# R7FA2L1AB register map
Vendor: Renesas Electronics Corporation; Series: RA2L1; File version: 1.30.00
CPU: CM23 r1p0, little endian, MPU, no FPU, VTOR, 2 interrupt priority bits, 32 interrupts
Registers are 8-bit, read-write, reset 0x0 unless marked. A register's access mark holds for its fields unless they carry their own. Offsets are from the block's base; [hi:lo] are bit positions; {n}, {i} and the like mark numbered series.

## ICU — ICU for CPU
Base 0x40006000
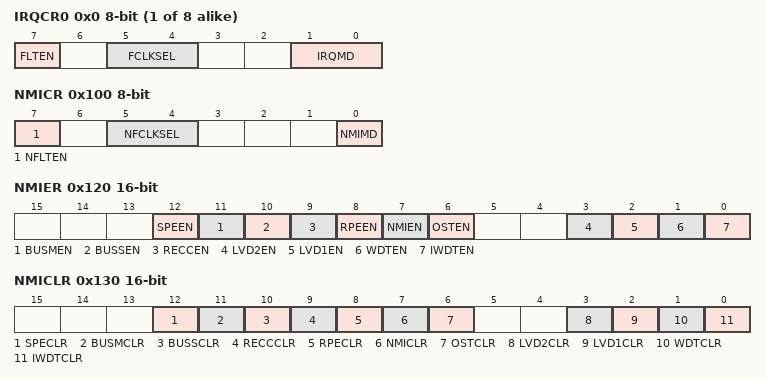
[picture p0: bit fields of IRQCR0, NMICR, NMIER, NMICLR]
{0x0+i} IRQCR{i} (i=0..7) — IRQ Control Register {i}
  [7] FLTEN — IRQi Digital Filter Enable
    0=Digital filter is disabled; 1=Digital filter is enabled
  [5:4] FCLKSEL — IRQi Digital Filter Sampling Clock Select
    0=PCLKB; 1=PCLKB/8; 2=PCLKB/32; 3=PCLKB/64
  [1:0] IRQMD — IRQi Detection Sense Select
    0=Falling edge; 1=Rising edge; 2=Rising and falling edges; 3=Low level
0x100 NMICR — NMI Pin Interrupt Control Register
  [7] NFLTEN — NMI Digital Filter Enable
    0=Disabled; 1=Enabled
  [5:4] NFCLKSEL — NMI Digital Filter Sampling Clock Select
    0=PCLKB; 1=PCLKB/8; 2=PCLKB/32; 3=PCLKB/64
  [0] NMIMD — NMI Detection Set
    0=Falling edge; 1=Rising edge
0x120 NMIER 16-bit — Non-Maskable Interrupt Enable Register
  [all] fields
    0=Disabled; 1=Enabled
  [12] SPEEN — CPU Stack Pointer Monitor Interrupt Enable
  [11] BUSMEN — Bus Master MPU Error Interrupt Enable
  [10] BUSSEN — Bus Slave MPU Error Interrupt Enable
  [9] RECCEN — SRAM ECC Error Interrupt Enable
  [8] RPEEN — SRAM Parity Error Interrupt Enable
  [7] NMIEN — NMI Pin Interrupt Enable
  [6] OSTEN — Main Clock Oscillation Stop Detection Interrupt Enable
  [3] LVD2EN — Voltage monitor 2 Interrupt Enable
  [2] LVD1EN — Voltage monitor 1 Interrupt Enable
  [1] WDTEN — WDT Underflow/Refresh Error Interrupt Enable
  [0] IWDTEN — IWDT Underflow/Refresh Error Interrupt Enable
0x130 NMICLR 16-bit — Non-Maskable Interrupt Status Clear Register
  [12] SPECLR — CPU Stack Pointer Monitor Interrupt Status Flag Clear
    0=No effect; 1=Clear the NMISR.SPEST flag
  [11] BUSMCLR — Bus Master MPU Error Interrupt Status Flag Clear
    0=No effect; 1=Clear the NMISR.BUSMST flag
  [10] BUSSCLR — Bus Slave MPU Error Interrupt Status Flag Clear
    0=No effect; 1=Clear the NMISR.BUSSST flag
  [9] RECCCLR — SRAM ECC Error Interrupt Status Flag Clear
    0=No effect; 1=Clear the NMISR.RECCST flag
  [8] RPECLR — SRAM Parity Error Interrupt Status Flag Clear
    0=No effect; 1=Clear the NMISR.RPEST flag
  [7] NMICLR — NMI Pin Interrupt Status Flag Clear
    0=No effect; 1=Clear the NMISR.NMIST flag
  [6] OSTCLR — Oscillation Stop Detection Interrupt Status Flag Clear
    0=No effect; 1=Clear the NMISR.OSTST flag
  [3] LVD2CLR — Voltage Monitor 2 Interrupt Status Flag Clear
    0=No effect; 1=Clear the NMISR.LVD2ST flag
  [2] LVD1CLR — Voltage Monitor 1 Interrupt Status Flag Clear
    0=No effect; 1=Clear the NMISR.LVD1ST flag
  [1] WDTCLR — WDT Underflow/Refresh Error Interrupt Status Flag Clear
    0=No effect; 1=Clear the NMISR.WDTST flag
  [0] IWDTCLR — IWDT Underflow/Refresh Error Interrupt Status Flag Clear
    0=No effect; 1=Clear the NMISR.IWDTST flag
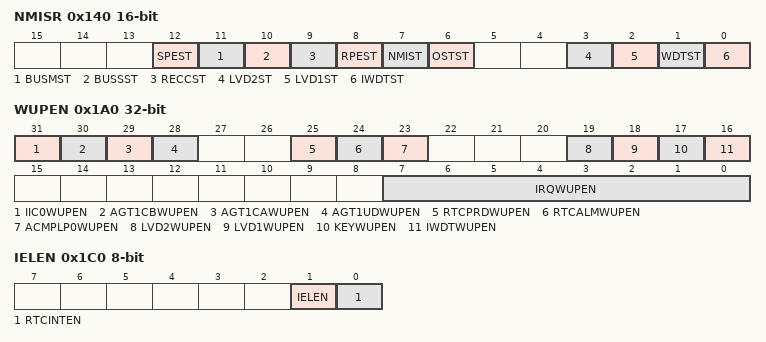
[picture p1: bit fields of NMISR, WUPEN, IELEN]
0x140 NMISR 16-bit ro — Non-Maskable Interrupt Status Register
  [12] SPEST — CPU Stack Pointer Monitor Interrupt Status Flag
    0=Interrupt not requested; 1=Interrupt requested
  [11] BUSMST — Bus Master MPU Error Interrupt Status Flag
    0=Interrupt not requested; 1=Interrupt requested
  [10] BUSSST — Bus Slave MPU Error Interrupt Status Flag
    0=Interrupt not requested; 1=Interrupt requested
  [9] RECCST — SRAM ECC Error Interrupt Status Flag
    0=Interrupt not requested; 1=Interrupt requested
  [8] RPEST — SRAM Parity Error Interrupt Status Flag
    0=Interrupt not requested; 1=Interrupt requested
  [7] NMIST — NMI Pin Interrupt Status Flag
    0=Interrupt not requested; 1=Interrupt requested
  [6] OSTST — Main Clock Oscillation Stop Detection Interrupt Status Flag
    0=Interrupt not requested for main clock oscillation stop; 1=Interrupt requested for main clock oscillation stop
  [3] LVD2ST — Voltage Monitor 2 Interrupt Status Flag
    0=Interrupt not requested; 1=Interrupt requested
  [2] LVD1ST — Voltage Monitor 1 Interrupt Status Flag
    0=Interrupt not requested; 1=Interrupt requested
  [1] WDTST — WDT Underflow/Refresh Error Interrupt Status Flag
    0=Interrupt not requested; 1=Interrupt requested
  [0] IWDTST — IWDT Underflow/Refresh Error Interrupt Status Flag
    0=Interrupt not requested; 1=Interrupt requested
0x1A0 WUPEN 32-bit — Wake Up Interrupt Enable Register
  [31] IIC0WUPEN — IIC0 Address Match Interrupt Software Standby/Snooze Mode Returns Enable
    0=Software Standby/Snooze Mode returns by IIC0 address match interrupt disabled; 1=Software Standby/Snooze Mode returns by IIC0 address match interrupt enabled
  [30] AGT1CBWUPEN — AGT1 Compare Match B Interrupt Software Standby/Snooze Mode Returns Enable
    0=Software Standby/Snooze Mode returns by AGT1 compare match B interrupt disabled; 1=Software Standby/Snooze Mode returns by AGT1 compare match B interrupt enabled
  [29] AGT1CAWUPEN — AGT1 Compare Match A Interrupt Software Standby/Snooze Mode Returns Enable
    0=Software Standby/Snooze Mode returns by AGT1 compare match A interrupt disabled; 1=Software Standby/Snooze Mode returns by AGT1 compare match A interrupt enabled
  [28] AGT1UDWUPEN — AGT1 Underflow Interrupt Software Standby/Snooze Mode Returns Enable
    0=Software Standby/Snooze Mode returns by AGT1 underflow interrupt disabled; 1=Software Standby/Snooze Mode returns by AGT1 underflow
  [25] RTCPRDWUPEN — RTC Period Interrupt Software Standby/Snooze Mode Returns Enable
    0=Software Standby/Snooze Mode returns by RTC period interrupt disabled; 1=Software Standby/Snooze Mode returns by RTC period interrupt enabled
  [24] RTCALMWUPEN — RTC Alarm Interrupt Software Standby/Snooze Mode Returns Enable
    0=Software Standby/Snooze Mode returns by RTC alarm interrupt disabled; 1=Software Standby/Snooze Mode returns by RTC alarm interrupt enabled
  [23] ACMPLP0WUPEN — ACMPLP0 Interrupt Software Standby/Snooze Mode Returns Enable
    0=Software Standby/Snooze Mode returns by ACMPLP0 interrupt disabled; 1=Software Standby/Snooze Mode returns by ACMPLP0 interrupt enabled
  [19] LVD2WUPEN — LVD2 Interrupt Software Standby/Snooze Mode Returns Enable
    0=Software Standby/Snooze Mode returns by LVD2 interrupt disabled; 1=Software Standby/Snooze Mode returns by LVD2 interrupt enabled
  [18] LVD1WUPEN — LVD1 Interrupt Software Standby/Snooze Mode Returns Enable
    0=Software Standby/Snooze Mode returns by LVD1 interrupt disabled; 1=Software Standby/Snooze Mode returns by LVD1 interrupt enabled
  [17] KEYWUPEN — Key Interrupt Software Standby/Snooze Mode Returns Enable
    0=Software Standby/Snooze Mode returns by KEY interrupt disabled; 1=Software Standby/Snooze Mode returns by KEY interrupt enabled
  [16] IWDTWUPEN — IWDT Interrupt Software Standby/Snooze Mode Returns Enable
    0=Software Standby/Snooze Mode returns by IWDT interrupt disabled; 1=Software Standby/Snooze Mode returns by IWDT interrupt enabled
  [7:0] IRQWUPEN — IRQ Interrupt Software Standby/Snooze Mode Returns Enable
    0=Software Standby/Snooze Mode returns by IRQn interrupt disabled; 1=Software Standby/Snooze Mode returns by IRQn interrupt enabled
0x1C0 IELEN — ICU event Enable Register
  [1] IELEN — Parts Asynchronous Interrupts Enable except RTC (when LPOPTEN bit = 1)
    0=Disabled; 1=Enabled
  [0] RTCINTEN — RTCALM and RTCPRD Interrupts Enable (when LPOPTEN bit = 1)
    0=Disabled; 1=Enabled
0x200 SELSR0 16-bit — SYS Event Link Setting Register
{0x300+4i} IELSR{i} (i=0..31) 32-bit — ICU Event Link Setting Register {i}

## Notices in the file
This software is supplied by Renesas Electronics Corporation and is only intended for
use with Renesas products. No other uses are authorized. This software is owned by
Renesas Electronics Corporation and is protected under all applicable laws, including
copyright laws.
THIS SOFTWARE IS PROVIDED "AS IS" AND RENESAS MAKES NO WARRANTIES REGARDING
THIS SOFTWARE, WHETHER EXPRESS, IMPLIED OR STATUTORY, INCLUDING BUT NOT LIMITED TO
WARRANTIES OF MERCHANTABILITY, FITNESS FOR A PARTICULAR PURPOSE AND NON-INFRINGEMENT.
ALL SUCH WARRANTIES ARE EXPRESSLY DISCLAIMED. TO THE MAXIMUM EXTENT PERMITTED NOT
PROHIBITED BY LAW, NEITHER RENESAS ELECTRONICS CORPORATION NOR ANY OF ITS AFFILIATED
COMPANIES SHALL BE LIABLE FOR ANY DIRECT, INDIRECT, SPECIAL, INCIDENTAL OR CONSEQUENTIAL
DAMAGES FOR ANY REASON RELATED TO THIS SOFTWARE, EVEN IF RENESAS OR ITS AFFILIATES HAVE
BEEN ADVISED OF THE POSSIBILITY OF SUCH DAMAGES.
Renesas reserves the right, without notice, to make changes to this software and to
discontinue the availability of this software. By using this software, you agree to
the additional terms and conditions found by accessing the following link:
http://www.renesas.com/disclaimer
